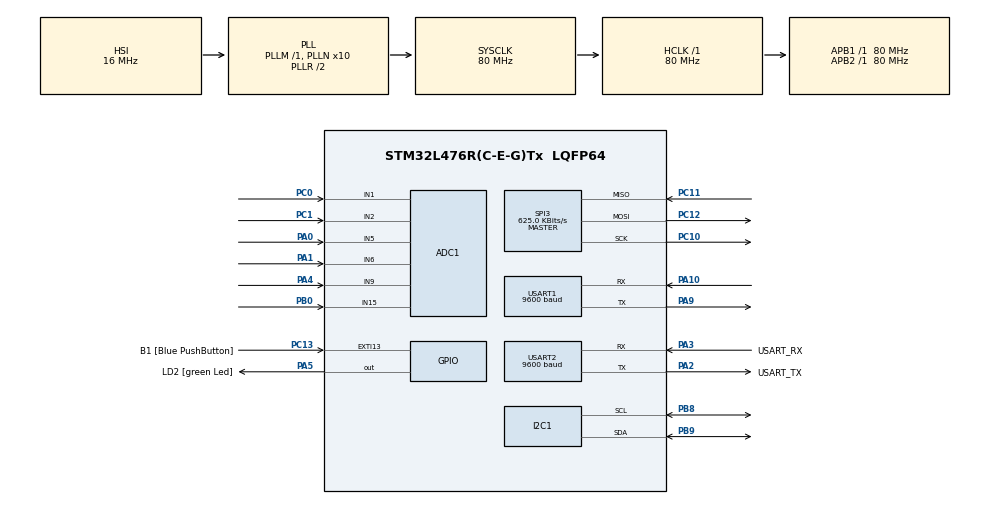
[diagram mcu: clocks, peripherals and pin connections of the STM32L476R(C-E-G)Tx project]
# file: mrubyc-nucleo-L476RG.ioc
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ADC1.Channel-0\#ChannelRegularConversion=ADC_CHANNEL_1
ADC1.NbrOfConversionFlag=1
ADC1.OffsetNumber-0\#ChannelRegularConversion=ADC_OFFSET_NONE
ADC1.Rank-0\#ChannelRegularConversion=1
ADC1.SamplingTime-0\#ChannelRegularConversion=ADC_SAMPLETIME_2CYCLES_5
ADC1.master=1
Dma.Request0=USART1_RX
Dma.Request1=USART2_RX
Dma.USART1_RX.0.Direction=DMA_PERIPH_TO_MEMORY
Dma.USART1_RX.0.Instance=DMA1_Channel5
Dma.USART1_RX.0.MemDataAlignment=DMA_MDATAALIGN_BYTE
Dma.USART1_RX.0.MemInc=DMA_MINC_ENABLE
Dma.USART1_RX.0.Mode=DMA_CIRCULAR
Dma.USART1_RX.0.PeriphDataAlignment=DMA_PDATAALIGN_BYTE
Dma.USART1_RX.0.PeriphInc=DMA_PINC_DISABLE
Dma.USART1_RX.0.Priority=DMA_PRIORITY_LOW
Dma.USART2_RX.1.Direction=DMA_PERIPH_TO_MEMORY
Dma.USART2_RX.1.Instance=DMA1_Channel6
Dma.USART2_RX.1.MemDataAlignment=DMA_MDATAALIGN_BYTE
Dma.USART2_RX.1.MemInc=DMA_MINC_ENABLE
Dma.USART2_RX.1.Mode=DMA_CIRCULAR
Dma.USART2_RX.1.PeriphDataAlignment=DMA_PDATAALIGN_BYTE
Dma.USART2_RX.1.PeriphInc=DMA_PINC_DISABLE
Dma.USART2_RX.1.Priority=DMA_PRIORITY_LOW
I2C1.Timing=0x10909CEC
Mcu.Family=STM32L4
Mcu.Name=STM32L476R(C-E-G)Tx
Mcu.Package=LQFP64
NVIC.DMA1_Channel5_IRQn=true\:0\:0\:false\:false\:true\:false\:true\:true
NVIC.DMA1_Channel6_IRQn=true\:0\:0\:false\:false\:true\:false\:true\:true
NVIC.PriorityGroup=NVIC_PRIORITYGROUP_4
PA0.Signal=ADCx_IN5
PA1.Signal=ADCx_IN6
PA10.Mode=Asynchronous
PA10.Signal=USART1_RX
PA13\ (JTMS-SWDIO).GPIO_Label=TMS
PA13\ (JTMS-SWDIO).Mode=Serial_Wire
PA13\ (JTMS-SWDIO).Signal=SYS_JTMS-SWDIO
PA14\ (JTCK-SWCLK).GPIO_Label=TCK
PA14\ (JTCK-SWCLK).Mode=Serial_Wire
PA14\ (JTCK-SWCLK).Signal=SYS_JTCK-SWCLK
PA2.GPIO_Label=USART_TX
PA2.GPIO_Mode=GPIO_MODE_AF_PP
PA2.GPIO_PuPd=GPIO_NOPULL
PA2.GPIO_Speed=GPIO_SPEED_FREQ_VERY_HIGH
PA2.Mode=Asynchronous
PA2.Signal=USART2_TX
PA3.GPIO_Label=USART_RX
PA3.GPIO_Mode=GPIO_MODE_AF_PP
PA3.GPIO_PuPd=GPIO_NOPULL
PA3.GPIO_Speed=GPIO_SPEED_FREQ_VERY_HIGH
PA3.Mode=Asynchronous
PA3.Signal=USART2_RX
PA4.Signal=ADCx_IN9
PA5.GPIO_Label=LD2 [green Led]
PA5.GPIO_ModeDefaultOutputPP=GPIO_MODE_OUTPUT_PP
PA5.GPIO_PuPd=GPIO_NOPULL
PA5.GPIO_Speed=GPIO_SPEED_FREQ_LOW
PA5.Signal=GPIO_Output
PA9.Mode=Asynchronous
PA9.Signal=USART1_TX
PB0.Signal=ADCx_IN15
PB3\ (JTDO-TRACESWO).GPIO_Label=SWO
PB3\ (JTDO-TRACESWO).Signal=SYS_JTDO-SWO
PB8.Mode=I2C
PB8.Signal=I2C1_SCL
PB9.Mode=I2C
PB9.Signal=I2C1_SDA
PC0.Signal=ADCx_IN1
PC1.Signal=ADCx_IN2
PC10.Mode=Full_Duplex_Master
PC10.Signal=SPI3_SCK
PC11.Mode=Full_Duplex_Master
PC11.Signal=SPI3_MISO
PC12.Mode=Full_Duplex_Master
PC12.Signal=SPI3_MOSI
PC13.GPIO_Label=B1 [Blue PushButton]
PC13.GPIO_ModeDefaultEXTI=GPIO_MODE_IT_FALLING
PC13.GPIO_PuPd=GPIO_NOPULL
PC13.Signal=GPXTI13
PC14-OSC32_IN\ (PC14).Mode=LSE-External-Oscillator
PC14-OSC32_IN\ (PC14).Signal=RCC_OSC32_IN
PC15-OSC32_OUT\ (PC15).Mode=LSE-External-Oscillator
PC15-OSC32_OUT\ (PC15).Signal=RCC_OSC32_OUT
PH0-OSC_IN\ (PH0).Signal=RCC_OSC_IN
PH1-OSC_OUT\ (PH1).Signal=RCC_OSC_OUT
ProjectManager.HeapSize=0x200
ProjectManager.StackSize=0x400
ProjectManager.TargetToolchain=STM32CubeIDE
RCC.ADCFreq_Value=64000000
RCC.AHBFreq_Value=80000000
RCC.APB1Freq_Value=80000000
RCC.APB1TimFreq_Value=80000000
RCC.APB2Freq_Value=80000000
RCC.APB2TimFreq_Value=80000000
RCC.CortexFreq_Value=80000000
RCC.HCLKFreq_Value=80000000
RCC.HSE_VALUE=8000000
RCC.HSI_VALUE=16000000
RCC.MSI_VALUE=4000000
RCC.PLLN=10
RCC.PLLSourceVirtual=RCC_PLLSOURCE_HSI
RCC.PREFETCH_ENABLE=1
RCC.SYSCLKFreq_VALUE=80000000
RCC.SYSCLKSource=RCC_SYSCLKSOURCE_PLLCLK
RCC.USBFreq_Value=64000000
RCC.VCOOutputFreq_Value=160000000
SH.ADCx_IN1.0=ADC1_IN1,IN1-Single-Ended
SH.ADCx_IN15.0=ADC1_IN15,IN15-Single-Ended
SH.ADCx_IN2.0=ADC1_IN2,IN2-Single-Ended
SH.ADCx_IN5.0=ADC1_IN5,IN5-Single-Ended
SH.ADCx_IN6.0=ADC1_IN6,IN6-Single-Ended
SH.ADCx_IN9.0=ADC1_IN9,IN9-Single-Ended
SPI3.BaudRatePrescaler=SPI_BAUDRATEPRESCALER_128
SPI3.CalculateBaudRate=625.0 KBits/s
SPI3.DataSize=SPI_DATASIZE_8BIT
SPI3.Direction=SPI_DIRECTION_2LINES
SPI3.Mode=SPI_MODE_MASTER
SPI3.VirtualType=VM_MASTER
TIM1.Channel-PWM\ Generation1\ No\ Output=TIM_CHANNEL_1
TIM2.Channel-PWM\ Generation1\ No\ Output=TIM_CHANNEL_1
TIM2.Channel-PWM\ Generation2\ No\ Output=TIM_CHANNEL_2
TIM2.Channel-PWM\ Generation3\ No\ Output=TIM_CHANNEL_3
TIM3.Channel-PWM\ Generation1\ No\ Output=TIM_CHANNEL_1
TIM3.Channel-PWM\ Generation2\ No\ Output=TIM_CHANNEL_2
TIM3.Channel-PWM\ Generation3\ No\ Output=TIM_CHANNEL_3
TIM4.Channel-PWM\ Generation1\ No\ Output=TIM_CHANNEL_1
USART1.BaudRate=9600
USART1.VirtualMode-Asynchronous=VM_ASYNC
USART2.BaudRate=9600
USART2.VirtualMode-Asynchronous=VM_ASYNC
VP_TIM1_VS_no_output1.Mode=PWM Generation1 No Output
VP_TIM2_VS_no_output1.Mode=PWM Generation1 No Output
VP_TIM2_VS_no_output2.Mode=PWM Generation2 No Output
VP_TIM2_VS_no_output3.Mode=PWM Generation3 No Output
VP_TIM3_VS_no_output1.Mode=PWM Generation1 No Output
VP_TIM3_VS_no_output2.Mode=PWM Generation2 No Output
VP_TIM3_VS_no_output3.Mode=PWM Generation3 No Output
VP_TIM4_VS_no_output1.Mode=PWM Generation1 No Output
board=NUCLEO-L476RG

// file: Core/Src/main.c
/* USER CODE BEGIN Header */
/**
  ******************************************************************************
  * @file           : main.c
  * @brief          : Main program body
  ******************************************************************************
  * @attention
  *
  * Copyright (c) 2024 STMicroelectronics.
  * All rights reserved.
  *
  * This software is licensed under terms that can be found in the LICENSE file
  * in the root directory of this software component.
  * If no LICENSE file comes with this software, it is provided AS-IS.
  *
  ******************************************************************************
  */
/* USER CODE END Header */
#include "main.h"

ADC_HandleTypeDef hadc1;

I2C_HandleTypeDef hi2c1;

SPI_HandleTypeDef hspi3;

TIM_HandleTypeDef htim1;
TIM_HandleTypeDef htim2;
TIM_HandleTypeDef htim3;
TIM_HandleTypeDef htim4;

UART_HandleTypeDef huart1;
UART_HandleTypeDef huart2;
DMA_HandleTypeDef hdma_usart1_rx;
DMA_HandleTypeDef hdma_usart2_rx;

void SystemClock_Config(void);
static void MX_GPIO_Init(void);
static void MX_DMA_Init(void);
static void MX_USART2_UART_Init(void);
static void MX_USART1_UART_Init(void);
static void MX_ADC1_Init(void);
static void MX_TIM1_Init(void);
static void MX_TIM2_Init(void);
static void MX_TIM3_Init(void);
static void MX_TIM4_Init(void);
static void MX_I2C1_Init(void);
static void MX_SPI3_Init(void);

int main(void)
{

  /* MCU Configuration--------------------------------------------------------*/

  /* Reset of all peripherals, Initializes the Flash interface and the Systick. */
  HAL_Init();

  /* Configure the system clock */
  SystemClock_Config();

  /* Initialize all configured peripherals */
  MX_GPIO_Init();
  MX_DMA_Init();
  MX_USART2_UART_Init();
  MX_USART1_UART_Init();
  MX_ADC1_Init();
  MX_TIM1_Init();
  MX_TIM2_Init();
  MX_TIM3_Init();
  MX_TIM4_Init();
  MX_I2C1_Init();
  MX_SPI3_Init();
  /* USER CODE BEGIN 2 */
  void start_mrubyc(void);
  start_mrubyc();

  /* USER CODE END 2 */

  /* Infinite loop */
  while (1)
  {

  }
}

void SystemClock_Config(void)
{
  RCC_OscInitTypeDef RCC_OscInitStruct = {0};
  RCC_ClkInitTypeDef RCC_ClkInitStruct = {0};

  /** Configure the main internal regulator output voltage
  */
  if (HAL_PWREx_ControlVoltageScaling(PWR_REGULATOR_VOLTAGE_SCALE1) != HAL_OK)
  {
    Error_Handler();
  }

  /** Initializes the RCC Oscillators according to the specified parameters
  * in the RCC_OscInitTypeDef structure.
  */
  RCC_OscInitStruct.OscillatorType = RCC_OSCILLATORTYPE_HSI;
  RCC_OscInitStruct.HSIState = RCC_HSI_ON;
  RCC_OscInitStruct.HSICalibrationValue = RCC_HSICALIBRATION_DEFAULT;
  RCC_OscInitStruct.PLL.PLLState = RCC_PLL_ON;
  RCC_OscInitStruct.PLL.PLLSource = RCC_PLLSOURCE_HSI;
  RCC_OscInitStruct.PLL.PLLM = 1;
  RCC_OscInitStruct.PLL.PLLN = 10;
  RCC_OscInitStruct.PLL.PLLP = RCC_PLLP_DIV7;
  RCC_OscInitStruct.PLL.PLLQ = RCC_PLLQ_DIV2;
  RCC_OscInitStruct.PLL.PLLR = RCC_PLLR_DIV2;
  if (HAL_RCC_OscConfig(&RCC_OscInitStruct) != HAL_OK)
  {
    Error_Handler();
  }

  /** Initializes the CPU, AHB and APB buses clocks
  */
  RCC_ClkInitStruct.ClockType = RCC_CLOCKTYPE_HCLK|RCC_CLOCKTYPE_SYSCLK
                              |RCC_CLOCKTYPE_PCLK1|RCC_CLOCKTYPE_PCLK2;
  RCC_ClkInitStruct.SYSCLKSource = RCC_SYSCLKSOURCE_PLLCLK;
  RCC_ClkInitStruct.AHBCLKDivider = RCC_SYSCLK_DIV1;
  RCC_ClkInitStruct.APB1CLKDivider = RCC_HCLK_DIV1;
  RCC_ClkInitStruct.APB2CLKDivider = RCC_HCLK_DIV1;

  if (HAL_RCC_ClockConfig(&RCC_ClkInitStruct, FLASH_LATENCY_4) != HAL_OK)
  {
    Error_Handler();
  }
}

static void MX_ADC1_Init(void)
{

  ADC_MultiModeTypeDef multimode = {0};
  ADC_ChannelConfTypeDef sConfig = {0};

  /** Common config
  */
  hadc1.Instance = ADC1;
  hadc1.Init.ClockPrescaler = ADC_CLOCK_ASYNC_DIV1;
  hadc1.Init.Resolution = ADC_RESOLUTION_12B;
  hadc1.Init.DataAlign = ADC_DATAALIGN_RIGHT;
  hadc1.Init.ScanConvMode = ADC_SCAN_DISABLE;
  hadc1.Init.EOCSelection = ADC_EOC_SINGLE_CONV;
  hadc1.Init.LowPowerAutoWait = DISABLE;
  hadc1.Init.ContinuousConvMode = DISABLE;
  hadc1.Init.NbrOfConversion = 1;
  hadc1.Init.DiscontinuousConvMode = DISABLE;
  hadc1.Init.ExternalTrigConv = ADC_SOFTWARE_START;
  hadc1.Init.ExternalTrigConvEdge = ADC_EXTERNALTRIGCONVEDGE_NONE;
  hadc1.Init.DMAContinuousRequests = DISABLE;
  hadc1.Init.Overrun = ADC_OVR_DATA_PRESERVED;
  hadc1.Init.OversamplingMode = DISABLE;
  if (HAL_ADC_Init(&hadc1) != HAL_OK)
  {
    Error_Handler();
  }

  /** Configure the ADC multi-mode
  */
  multimode.Mode = ADC_MODE_INDEPENDENT;
  if (HAL_ADCEx_MultiModeConfigChannel(&hadc1, &multimode) != HAL_OK)
  {
    Error_Handler();
  }

  /** Configure Regular Channel
  */
  sConfig.Channel = ADC_CHANNEL_1;
  sConfig.Rank = ADC_REGULAR_RANK_1;
  sConfig.SamplingTime = ADC_SAMPLETIME_2CYCLES_5;
  sConfig.SingleDiff = ADC_SINGLE_ENDED;
  sConfig.OffsetNumber = ADC_OFFSET_NONE;
  sConfig.Offset = 0;
  if (HAL_ADC_ConfigChannel(&hadc1, &sConfig) != HAL_OK)
  {
    Error_Handler();
  }

}

static void MX_I2C1_Init(void)
{

  hi2c1.Instance = I2C1;
  hi2c1.Init.Timing = 0x10909CEC;
  hi2c1.Init.OwnAddress1 = 0;
  hi2c1.Init.AddressingMode = I2C_ADDRESSINGMODE_7BIT;
  hi2c1.Init.DualAddressMode = I2C_DUALADDRESS_DISABLE;
  hi2c1.Init.OwnAddress2 = 0;
  hi2c1.Init.OwnAddress2Masks = I2C_OA2_NOMASK;
  hi2c1.Init.GeneralCallMode = I2C_GENERALCALL_DISABLE;
  hi2c1.Init.NoStretchMode = I2C_NOSTRETCH_DISABLE;
  if (HAL_I2C_Init(&hi2c1) != HAL_OK)
  {
    Error_Handler();
  }

  /** Configure Analogue filter
  */
  if (HAL_I2CEx_ConfigAnalogFilter(&hi2c1, I2C_ANALOGFILTER_ENABLE) != HAL_OK)
  {
    Error_Handler();
  }

  /** Configure Digital filter
  */
  if (HAL_I2CEx_ConfigDigitalFilter(&hi2c1, 0) != HAL_OK)
  {
    Error_Handler();
  }

}

static void MX_SPI3_Init(void)
{

  /* SPI3 parameter configuration*/
  hspi3.Instance = SPI3;
  hspi3.Init.Mode = SPI_MODE_MASTER;
  hspi3.Init.Direction = SPI_DIRECTION_2LINES;
  hspi3.Init.DataSize = SPI_DATASIZE_8BIT;
  hspi3.Init.CLKPolarity = SPI_POLARITY_LOW;
  hspi3.Init.CLKPhase = SPI_PHASE_1EDGE;
  hspi3.Init.NSS = SPI_NSS_SOFT;
  hspi3.Init.BaudRatePrescaler = SPI_BAUDRATEPRESCALER_128;
  hspi3.Init.FirstBit = SPI_FIRSTBIT_MSB;
  hspi3.Init.TIMode = SPI_TIMODE_DISABLE;
  hspi3.Init.CRCCalculation = SPI_CRCCALCULATION_DISABLE;
  hspi3.Init.CRCPolynomial = 7;
  hspi3.Init.CRCLength = SPI_CRC_LENGTH_DATASIZE;
  hspi3.Init.NSSPMode = SPI_NSS_PULSE_ENABLE;
  if (HAL_SPI_Init(&hspi3) != HAL_OK)
  {
    Error_Handler();
  }

}

static void MX_TIM1_Init(void)
{

  TIM_MasterConfigTypeDef sMasterConfig = {0};
  TIM_OC_InitTypeDef sConfigOC = {0};
  TIM_BreakDeadTimeConfigTypeDef sBreakDeadTimeConfig = {0};

  htim1.Instance = TIM1;
  htim1.Init.Prescaler = 0;
  htim1.Init.CounterMode = TIM_COUNTERMODE_UP;
  htim1.Init.Period = 65535;
  htim1.Init.ClockDivision = TIM_CLOCKDIVISION_DIV1;
  htim1.Init.RepetitionCounter = 0;
  htim1.Init.AutoReloadPreload = TIM_AUTORELOAD_PRELOAD_DISABLE;
  if (HAL_TIM_PWM_Init(&htim1) != HAL_OK)
  {
    Error_Handler();
  }
  sMasterConfig.MasterOutputTrigger = TIM_TRGO_RESET;
  sMasterConfig.MasterOutputTrigger2 = TIM_TRGO2_RESET;
  sMasterConfig.MasterSlaveMode = TIM_MASTERSLAVEMODE_DISABLE;
  if (HAL_TIMEx_MasterConfigSynchronization(&htim1, &sMasterConfig) != HAL_OK)
  {
    Error_Handler();
  }
  sConfigOC.OCMode = TIM_OCMODE_PWM1;
  sConfigOC.Pulse = 0;
  sConfigOC.OCPolarity = TIM_OCPOLARITY_HIGH;
  sConfigOC.OCNPolarity = TIM_OCNPOLARITY_HIGH;
  sConfigOC.OCFastMode = TIM_OCFAST_DISABLE;
  sConfigOC.OCIdleState = TIM_OCIDLESTATE_RESET;
  sConfigOC.OCNIdleState = TIM_OCNIDLESTATE_RESET;
  if (HAL_TIM_PWM_ConfigChannel(&htim1, &sConfigOC, TIM_CHANNEL_1) != HAL_OK)
  {
    Error_Handler();
  }
  sBreakDeadTimeConfig.OffStateRunMode = TIM_OSSR_DISABLE;
  sBreakDeadTimeConfig.OffStateIDLEMode = TIM_OSSI_DISABLE;
  sBreakDeadTimeConfig.LockLevel = TIM_LOCKLEVEL_OFF;
  sBreakDeadTimeConfig.DeadTime = 0;
  sBreakDeadTimeConfig.BreakState = TIM_BREAK_DISABLE;
  sBreakDeadTimeConfig.BreakPolarity = TIM_BREAKPOLARITY_HIGH;
  sBreakDeadTimeConfig.BreakFilter = 0;
  sBreakDeadTimeConfig.Break2State = TIM_BREAK2_DISABLE;
  sBreakDeadTimeConfig.Break2Polarity = TIM_BREAK2POLARITY_HIGH;
  sBreakDeadTimeConfig.Break2Filter = 0;
  sBreakDeadTimeConfig.AutomaticOutput = TIM_AUTOMATICOUTPUT_DISABLE;
  if (HAL_TIMEx_ConfigBreakDeadTime(&htim1, &sBreakDeadTimeConfig) != HAL_OK)
  {
    Error_Handler();
  }

}

static void MX_TIM2_Init(void)
{

  TIM_MasterConfigTypeDef sMasterConfig = {0};
  TIM_OC_InitTypeDef sConfigOC = {0};

  htim2.Instance = TIM2;
  htim2.Init.Prescaler = 0;
  htim2.Init.CounterMode = TIM_COUNTERMODE_UP;
  htim2.Init.Period = 4294967295;
  htim2.Init.ClockDivision = TIM_CLOCKDIVISION_DIV1;
  htim2.Init.AutoReloadPreload = TIM_AUTORELOAD_PRELOAD_DISABLE;
  if (HAL_TIM_PWM_Init(&htim2) != HAL_OK)
  {
    Error_Handler();
  }
  sMasterConfig.MasterOutputTrigger = TIM_TRGO_RESET;
  sMasterConfig.MasterSlaveMode = TIM_MASTERSLAVEMODE_DISABLE;
  if (HAL_TIMEx_MasterConfigSynchronization(&htim2, &sMasterConfig) != HAL_OK)
  {
    Error_Handler();
  }
  sConfigOC.OCMode = TIM_OCMODE_PWM1;
  sConfigOC.Pulse = 0;
  sConfigOC.OCPolarity = TIM_OCPOLARITY_HIGH;
  sConfigOC.OCFastMode = TIM_OCFAST_DISABLE;
  if (HAL_TIM_PWM_ConfigChannel(&htim2, &sConfigOC, TIM_CHANNEL_1) != HAL_OK)
  {
    Error_Handler();
  }
  if (HAL_TIM_PWM_ConfigChannel(&htim2, &sConfigOC, TIM_CHANNEL_2) != HAL_OK)
  {
    Error_Handler();
  }
  if (HAL_TIM_PWM_ConfigChannel(&htim2, &sConfigOC, TIM_CHANNEL_3) != HAL_OK)
  {
    Error_Handler();
  }

}

static void MX_TIM3_Init(void)
{

  TIM_MasterConfigTypeDef sMasterConfig = {0};
  TIM_OC_InitTypeDef sConfigOC = {0};

  htim3.Instance = TIM3;
  htim3.Init.Prescaler = 0;
  htim3.Init.CounterMode = TIM_COUNTERMODE_UP;
  htim3.Init.Period = 65535;
  htim3.Init.ClockDivision = TIM_CLOCKDIVISION_DIV1;
  htim3.Init.AutoReloadPreload = TIM_AUTORELOAD_PRELOAD_DISABLE;
  if (HAL_TIM_PWM_Init(&htim3) != HAL_OK)
  {
    Error_Handler();
  }
  sMasterConfig.MasterOutputTrigger = TIM_TRGO_RESET;
  sMasterConfig.MasterSlaveMode = TIM_MASTERSLAVEMODE_DISABLE;
  if (HAL_TIMEx_MasterConfigSynchronization(&htim3, &sMasterConfig) != HAL_OK)
  {
    Error_Handler();
  }
  sConfigOC.OCMode = TIM_OCMODE_PWM1;
  sConfigOC.Pulse = 0;
  sConfigOC.OCPolarity = TIM_OCPOLARITY_HIGH;
  sConfigOC.OCFastMode = TIM_OCFAST_DISABLE;
  if (HAL_TIM_PWM_ConfigChannel(&htim3, &sConfigOC, TIM_CHANNEL_1) != HAL_OK)
  {
    Error_Handler();
  }
  if (HAL_TIM_PWM_ConfigChannel(&htim3, &sConfigOC, TIM_CHANNEL_2) != HAL_OK)
  {
    Error_Handler();
  }
  if (HAL_TIM_PWM_ConfigChannel(&htim3, &sConfigOC, TIM_CHANNEL_3) != HAL_OK)
  {
    Error_Handler();
  }

}

static void MX_TIM4_Init(void)
{

  TIM_MasterConfigTypeDef sMasterConfig = {0};
  TIM_OC_InitTypeDef sConfigOC = {0};

  htim4.Instance = TIM4;
  htim4.Init.Prescaler = 0;
  htim4.Init.CounterMode = TIM_COUNTERMODE_UP;
  htim4.Init.Period = 65535;
  htim4.Init.ClockDivision = TIM_CLOCKDIVISION_DIV1;
  htim4.Init.AutoReloadPreload = TIM_AUTORELOAD_PRELOAD_DISABLE;
  if (HAL_TIM_PWM_Init(&htim4) != HAL_OK)
  {
    Error_Handler();
  }
  sMasterConfig.MasterOutputTrigger = TIM_TRGO_RESET;
  sMasterConfig.MasterSlaveMode = TIM_MASTERSLAVEMODE_DISABLE;
  if (HAL_TIMEx_MasterConfigSynchronization(&htim4, &sMasterConfig) != HAL_OK)
  {
    Error_Handler();
  }
  sConfigOC.OCMode = TIM_OCMODE_PWM1;
  sConfigOC.Pulse = 0;
  sConfigOC.OCPolarity = TIM_OCPOLARITY_HIGH;
  sConfigOC.OCFastMode = TIM_OCFAST_DISABLE;
  if (HAL_TIM_PWM_ConfigChannel(&htim4, &sConfigOC, TIM_CHANNEL_1) != HAL_OK)
  {
    Error_Handler();
  }

}

static void MX_USART1_UART_Init(void)
{

  huart1.Instance = USART1;
  huart1.Init.BaudRate = 9600;
  huart1.Init.WordLength = UART_WORDLENGTH_8B;
  huart1.Init.StopBits = UART_STOPBITS_1;
  huart1.Init.Parity = UART_PARITY_NONE;
  huart1.Init.Mode = UART_MODE_TX_RX;
  huart1.Init.HwFlowCtl = UART_HWCONTROL_NONE;
  huart1.Init.OverSampling = UART_OVERSAMPLING_16;
  huart1.Init.OneBitSampling = UART_ONE_BIT_SAMPLE_DISABLE;
  huart1.AdvancedInit.AdvFeatureInit = UART_ADVFEATURE_NO_INIT;
  if (HAL_UART_Init(&huart1) != HAL_OK)
  {
    Error_Handler();
  }

}

static void MX_USART2_UART_Init(void)
{

  huart2.Instance = USART2;
  huart2.Init.BaudRate = 9600;
  huart2.Init.WordLength = UART_WORDLENGTH_8B;
  huart2.Init.StopBits = UART_STOPBITS_1;
  huart2.Init.Parity = UART_PARITY_NONE;
  huart2.Init.Mode = UART_MODE_TX_RX;
  huart2.Init.HwFlowCtl = UART_HWCONTROL_NONE;
  huart2.Init.OverSampling = UART_OVERSAMPLING_16;
  huart2.Init.OneBitSampling = UART_ONE_BIT_SAMPLE_DISABLE;
  huart2.AdvancedInit.AdvFeatureInit = UART_ADVFEATURE_NO_INIT;
  if (HAL_UART_Init(&huart2) != HAL_OK)
  {
    Error_Handler();
  }

}

static void MX_DMA_Init(void)
{

  /* DMA controller clock enable */
  __HAL_RCC_DMA1_CLK_ENABLE();

  /* DMA interrupt init */
  /* DMA1_Channel5_IRQn interrupt configuration */
  HAL_NVIC_SetPriority(DMA1_Channel5_IRQn, 0, 0);
  HAL_NVIC_EnableIRQ(DMA1_Channel5_IRQn);
  /* DMA1_Channel6_IRQn interrupt configuration */
  HAL_NVIC_SetPriority(DMA1_Channel6_IRQn, 0, 0);
  HAL_NVIC_EnableIRQ(DMA1_Channel6_IRQn);

}

static void MX_GPIO_Init(void)
{
  GPIO_InitTypeDef GPIO_InitStruct = {0};

  /* GPIO Ports Clock Enable */
  __HAL_RCC_GPIOC_CLK_ENABLE();
  __HAL_RCC_GPIOH_CLK_ENABLE();
  __HAL_RCC_GPIOA_CLK_ENABLE();
  __HAL_RCC_GPIOB_CLK_ENABLE();

  /*Configure GPIO pin Output Level */
  HAL_GPIO_WritePin(LD2_GPIO_Port, LD2_Pin, GPIO_PIN_RESET);

  /*Configure GPIO pin : B1_Pin */
  GPIO_InitStruct.Pin = B1_Pin;
  GPIO_InitStruct.Mode = GPIO_MODE_IT_FALLING;
  GPIO_InitStruct.Pull = GPIO_NOPULL;
  HAL_GPIO_Init(B1_GPIO_Port, &GPIO_InitStruct);

  /*Configure GPIO pin : LD2_Pin */
  GPIO_InitStruct.Pin = LD2_Pin;
  GPIO_InitStruct.Mode = GPIO_MODE_OUTPUT_PP;
  GPIO_InitStruct.Pull = GPIO_NOPULL;
  GPIO_InitStruct.Speed = GPIO_SPEED_FREQ_LOW;
  HAL_GPIO_Init(LD2_GPIO_Port, &GPIO_InitStruct);

}

void Error_Handler(void)
{
  __disable_irq();
  while (1)
  {
  }
}
